# AM13E230x register map
Vendor: Texas Instruments; File version: Revised: 2025-12-26 17:30:06
CPU: CM33 r0p0, little endian, MPU, FPU, 4 interrupt priority bits
Registers are 32-bit, read-write, reset 0x0 unless marked. A register's access mark holds for its fields unless they carry their own. Offsets are from the block's base; [hi:lo] are bit positions; lines under a group give offsets from that group; {n}, {i} and the like mark numbered series; 'fields as' and 'values as' point back to an identical list.

## MEMCFG — MEM_CFG_REGS
Base 0x4002A000
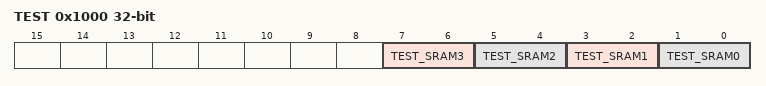
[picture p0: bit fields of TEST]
0x1000 TEST — RAM TEST Register
  [7:6] TEST_SRAM3 — Selects the different test modes for UGLXMP_2 RAM
  [5:4] TEST_SRAM2 — Selects the different test modes for GLXMP_1 RAM
  [3:2] TEST_SRAM1 — Selects the different test modes for GLXMP_0 RAM
  [1:0] TEST_SRAM0 — Selects the different test modes for ULL RAM
0x1010 ROM_WS_CONFIG — ROM wait state configuration
  [0] ROM_WS_ENABLE — ROM wait state 1 enable
0x1014 TMUROM_TEST reset 0x5 — ROM wait state configuration
  [3:0] TMUROM_PAR_FORCE — ROM wait state 1 enable

## PGA0 — PGA_REGS
Base 0x400FC000
Same registers: PGA1 0x400FD000, PGA2 0x400FE000
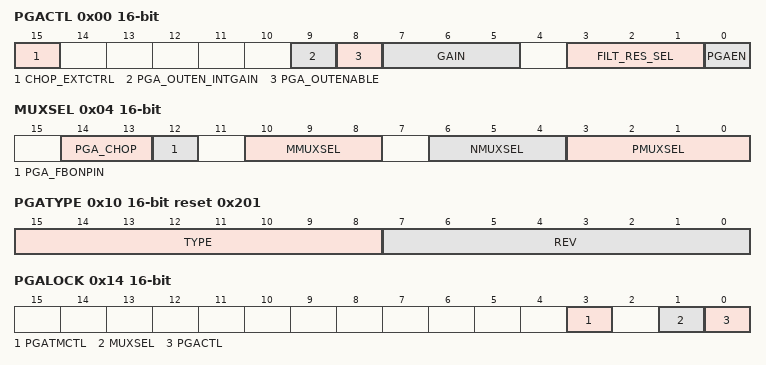
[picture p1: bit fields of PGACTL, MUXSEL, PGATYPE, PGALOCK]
0x00 PGACTL 16-bit — PGA Control Register
  [15] CHOP_EXTCTRL — External Chop Signal Control
  [9] PGA_OUTEN_INTGAIN — PGA Internal Gain Output Enable
  [8] PGA_OUTENABLE — PGA Output Enable
  [7:5] GAIN — PGA gain setting
  [3:1] FILT_RES_SEL — Filter Resistor Select
  [0] PGAEN — PGA Enable
0x04 MUXSEL 16-bit — Mux Selection Register
  [14:13] PGA_CHOP — Chopper Mode Control
  [12] PGA_FBONPIN — Connect PGAOUT to PGA_INM
  [10:8] MMUXSEL — M Mux Select
  [6:4] NMUXSEL — Negative Input Mux Select
  [3:0] PMUXSEL — Positive Input Mux Select
0x10 PGATYPE 16-bit reset 0x201
  [15:8] TYPE ro — PGA Type Field
  [7:0] REV ro — PGA Revision Field
0x14 PGALOCK 16-bit
  [3] PGATMCTL wo — Lock but for PGATMCTL
  [1] MUXSEL wo — Lock bit for MUXSEL
  [0] PGACTL wo — Lock bit for PGACTL.

## TINIELITE — PERIPHERALREGION
Base 0x408FF000
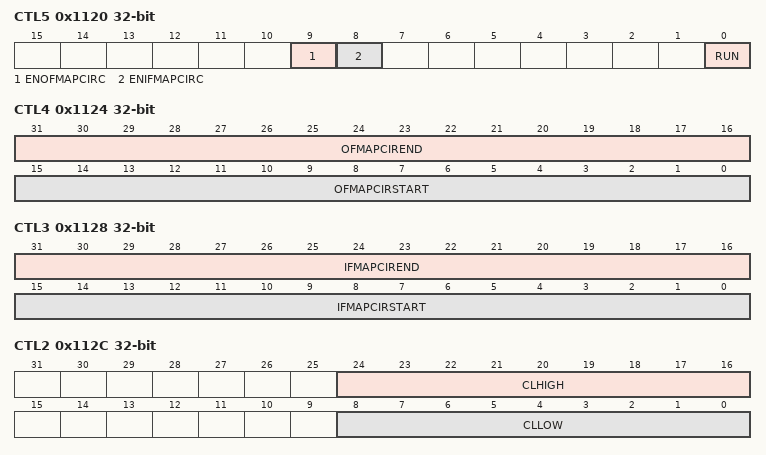
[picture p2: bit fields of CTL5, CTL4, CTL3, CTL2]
0x1120 CTL5
  [9] ENOFMAPCIRC — Enable circular addressing on output feature map read address.
    0=DISABLE (Disable circular buffering on the output feature map); 1=ENABLE (Enable circular buffering on the output feature map)
  [8] ENIFMAPCIRC — Enable circular addressing on input feature map read address.
    0=DISABLE; 1=ENABLE (Enable circular buffering on the input feature map)
  [0] RUN — Start the accelerator. Writing a 1 to this bit starts the accelerator. When the STOP instruction is executed this bit is cleared by hardware and DONE interrupt flag is set.
0x1124 CTL4
  [31:16] OFMAPCIREND — Circular buffer output feature map end address.
  [15:0] OFMAPCIRSTART — Circular buffer output feature map start address.
0x1128 CTL3
  [31:16] IFMAPCIREND — Circular buffer input feature map end address
  [15:0] IFMAPCIRSTART — Circular buffer input feature map start address
0x112C CTL2
  [24:16] CLHIGH — Upper clamp value
  [8:0] CLLOW — Lower clamp value
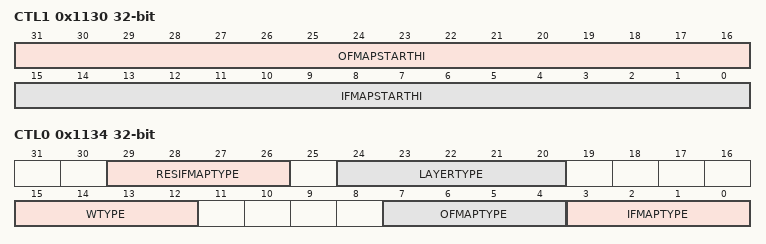
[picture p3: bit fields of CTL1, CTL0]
0x1130 CTL1
  [31:16] OFMAPSTARTHI — Start address (Higher 16 bits) of output feature map data.
  [15:0] IFMAPSTARTHI — Start address (Higher 16 bits) of input feature map data.
0x1134 CTL0
  [29:26] RESIFMAPTYPE — Residual Input feature map type,
    0=UNSIGNED_16BIT; 1=UNSIGNED_8BIT (Unsigned 8 bit data type); 2=UNSIGNED_4BIT (Unsigned 4 bit data type); 8=SIGNED_16BIT; 9=SIGNED_8BIT (Signed 8 bit data type); 10=SIGNED_4BIT (Signed 4 bit data type)
  [24:20] LAYERTYPE
    0=FCONV; 2=DW; 3=PW; 5=CONV; 6=FC; 7=AVGPOOL; 8=MAXPOOL; 16=FCONV_RESIDUAL; 18=DW_RESIDUAL; 19=PW_RESIDUAL; 21=CONV_RESIDUAL; 22=FC_RESIDUAL; 23=AVGPOOL_RESIDUAL; 24=MAXPOOL_RESIDUAL
  [15:12] WTYPE — Weight Type
    0=_2T (+1,-1,0); 1=BINARY (Binary data type, +1 or -1); 2=SIGNED_2BIT (Unsigned 8 bit data type); 3=SIGNED_4BIT (Signed 4 bit data type); 4=SIGNED_8BIT (Signed 8 bit data type)
  [7:4] OFMAPTYPE — Output feature map type.
    0=UNSIGNED_16BIT; 1=UNSIGNED_8BIT (Unsigned 8 bit data type); 2=UNSIGNED_4BIT (Unsigned 4 bit data type); 3=BINARY (Binary data type); 8=SIGNED_16BIT; 9=SIGNED_8BIT (Signed 8 bit data type); 10=SIGNED_4BIT (Signed 4 bit data type)
  [3:0] IFMAPTYPE — Input feature map type,
    values as OFMAPTYPE
{0x1138+0x18*i} LCREG[{i}] (i=0..0) group
  {0x0+4j} LC[{j}] (j=0..5) — Loop count registers.
    [15:0] CNT — Loop count.
0x1150 PC — Program count register
  [15:0] VALUE — Program count value.
{0x1154+0x50*i} ADDRREG[{i}] (i=0..0) group
  {0x0+4j} AREG[{j}] (j=0..19) — Address registers.
    [15:0] DATA — Data word.
{0x1710+4i} DATAIN[{i}] (i=0..1) — Input Data registers, used to load data from memory.
0x1720 DATAOUT — Output Data registers, used to store data to memory.
0x1730 SS0LOW — Scale and shift register 0, lower 32 bits.
0x1734 SS0HIGH — Scale and shift register 0, upper 32 bits.
0x1738 SS1LOW — Scale and shift register 1, lower 32 bits.
0x173C SS1HIGH — Scale and shift register 1, upper 32 bits.
0x1750 WGHT0LOW — Weight register 0, lower 32 bits.
0x1754 WGHT0HIGH — Weight register 0, upper 32 bits.
0x1758 WGHT1LOW — Weight register 1, lower 32 bits.
0x175C WGHT1HIGH — Weight register 1, upper 32 bits.
{0x1C00+0x80*i} ACCREG[{i}] (i=0..0) group
  {0x0+4j} ACCVAL[{j}] (j=0..31) — Register file data.
    [17:0] DATA — Data word.
{0x2000+0x400*i} INSTMEM[{i}] (i=0..0) group
  {0x0+4j} INSTMEM_INSTMEM[{j}] (j=0..255) — Instruction memory word.
{0x2800+0x800*i} REGFILE[{i}] (i=0..0) group
  {0x0+4j} RFDATA[{j}] (j=0..511) — Register file data.
